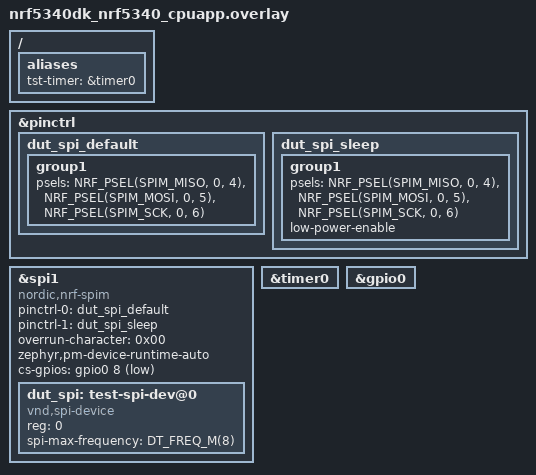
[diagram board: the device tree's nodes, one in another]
/*
 * Copyright (c) 2025 Nordic Semiconductor ASA
 *
 * SPDX-License-Identifier: LicenseRef-Nordic-5-Clause
 */

/* Required loopbacks:
 * P0.04 <-> P0.05
 */

/ {
	aliases {
		tst-timer = &timer0;
	};
};

&pinctrl {
	dut_spi_default: dut_spi_default {
		group1 {
			psels = <NRF_PSEL(SPIM_MISO, 0, 4)>,
				<NRF_PSEL(SPIM_MOSI, 0, 5)>,
				<NRF_PSEL(SPIM_SCK, 0, 6)>;
		};
	};

	dut_spi_sleep: dut_spi_sleep {
		group1 {
			psels = <NRF_PSEL(SPIM_MISO, 0, 4)>,
				<NRF_PSEL(SPIM_MOSI, 0, 5)>,
				<NRF_PSEL(SPIM_SCK, 0, 6)>;
			low-power-enable;
		};
	};
};

&spi1 {
	compatible = "nordic,nrf-spim";
	status = "okay";
	pinctrl-0 = <&dut_spi_default>;
	pinctrl-1 = <&dut_spi_sleep>;
	pinctrl-names = "default", "sleep";
	overrun-character = <0x00>;
	zephyr,pm-device-runtime-auto;
	cs-gpios = <&gpio0 8 GPIO_ACTIVE_LOW>;

	dut_spi: test-spi-dev@0 {
		compatible = "vnd,spi-device";
		reg = <0>;
		spi-max-frequency = <DT_FREQ_M(8)>;
	};
};

&timer0 {
	status = "okay";
};

&gpio0 {
	status = "okay";
};
